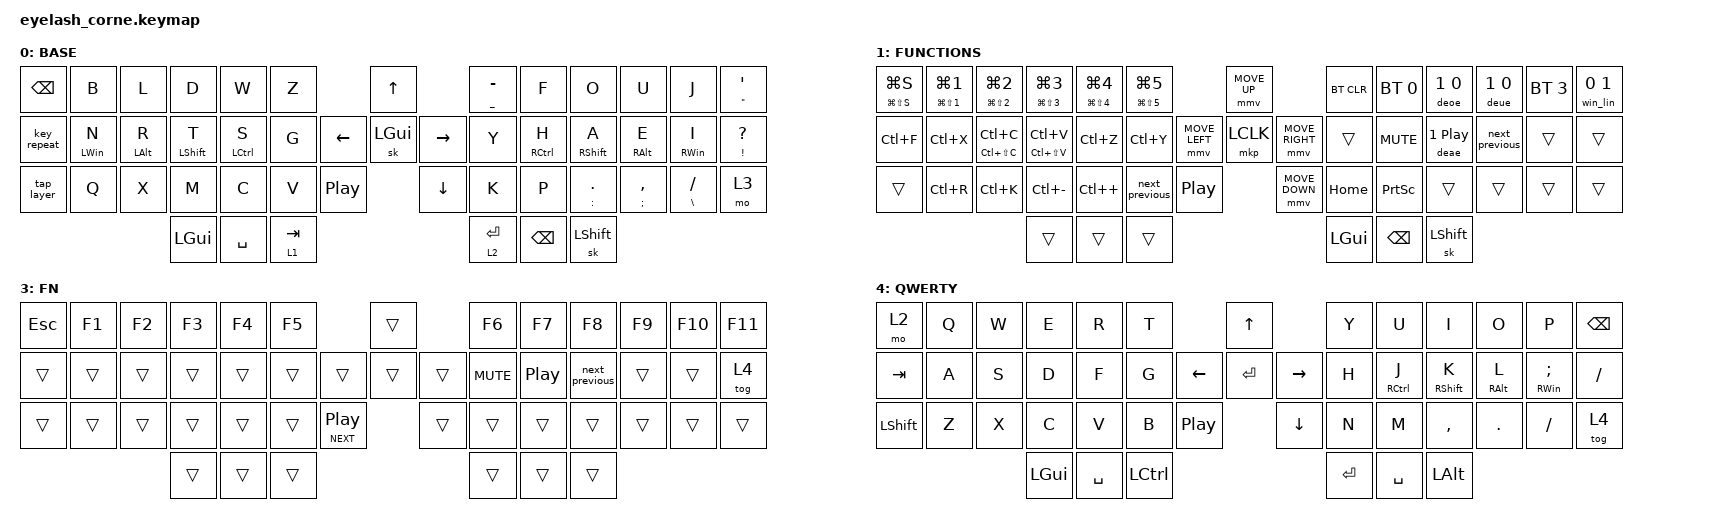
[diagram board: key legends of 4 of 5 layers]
#include <behaviors.dtsi>
#include <behaviors/unicode.dtsi> // for zmk-unicode

/* ----- For default ZMK behavior ---- */
#include <dt-bindings/zmk/bt.h>
#include <dt-bindings/zmk/keys.h>

#include <dt-bindings/zmk/mouse.h>
#include <dt-bindings/zmk/pointing.h>
#include <dt-bindings/zmk/outputs.h>
#include <dt-bindings/zmk/rgb.h>
#include <dt-bindings/zmk/pointing.h>
#include <dt-bindings/zmk/behaviors.h>

/* ----- Extra zmk modules ---- */
#include <zmk-unicode/keys-extra.h>
#include "zmk-helpers/helper.h"
#include <input/processors.dtsi>
#include "zmk-helpers/german.dtsi"
#include "german.dtsi"


/* Mouse input processing default values*/
#undef ZMK_MOUSE_DEFAULT_MOVE_VAL
#undef ZMK_MOUSE_DEFAULT_SCRL_VAL
#define ZMK_MOUSE_DEFAULT_MOVE_VAL 1000  // 600
#define ZMK_MOUSE_DEFAULT_SCRL_VAL 20   // 10

#define ZMK_POINTING_DEFAULT_MOVE_VAL 800  // default: 600
#define ZMK_POINTING_DEFAULT_SCRL_VAL 100    // default: 10
 

&mmv {
  acceleration-exponent = <1>;      // 1
  time-to-max-speed-ms = <500>;     // 300
  delay-ms = <0>;                   // 0
};

&msc {
  acceleration-exponent = <1>;      // 0
  time-to-max-speed-ms = <150>;     // 300
  delay-ms = <0>;                   // 0
};

 &uc {
  default-mode = <UC_MODE_WIN_COMPOSE>;
  minimum-length = <0>; 
}; 

/ {
    behaviors {
        td0: td0 {
            compatible = "zmk,behavior-tap-dance";
            display-name = "Shift/Caps Lock Tap Dance";
            #binding-cells = <0>;
            bindings = <&kp LEFT_SHIFT>, <&kp CAPS>;
        };

        Tab_switching: Tab_switching {
            compatible = "zmk,behavior-sensor-rotate";
            label = "TAB_SWITCHING";
            #sensor-binding-cells = <0>;
            bindings = <&kp LC(LA(TAB))>, <&kp LC(LA(LS(TAB)))>;   
        };

        App_switching: App_switching {
            compatible = "zmk,behavior-sensor-rotate";
            label = "APP_SWITCHING";
            #sensor-binding-cells = <0>;
            bindings = <&kp LG(TAB)>, <&kp LG(LS(TAB))>;
        };

        tap_layer: tap_layer {
            compatible = "zmk,behavior-tap-dance";
            label = "TAP_LAYER";
            #binding-cells = <0>;
            bindings = <&mo 2>, <&kp CAPSLOCK>;
        };

        next_previous: next_previous {
            compatible = "zmk,behavior-tap-dance";
            label = "NEXT_PREVIOUS";
            #binding-cells = <0>;
            bindings = <&kp C_NEXT>, <&kp C_PREVIOUS>;
        };

        rgb_encoder: rgb_encoder {
            compatible = "zmk,behavior-sensor-rotate";
            #sensor-binding-cells = <0>;
            bindings = <&rgb_ug RGB_BRI>, <&rgb_ug RGB_BRD>;
        };


        scroll_encoder: scroll_encoder {
			compatible = "zmk,behavior-sensor-rotate";
			#sensor-binding-cells = <0>;
			bindings = <&msc SCRL_DOWN>, <&msc SCRL_UP>;
			tap-ms = <62>;
		};

        op: op {
            compatible = "zmk,behavior-hold-tap";
            #binding-cells = <2>;
            flavor = "hold-preferred";
            tapping-term-ms = <200>;
            bindings = <&uc>, <&uc>;
            display-name = "Mod-Tap";
        };
    
        
    };

    

    combos { compatible = "zmk,combos"; 

        esc_q_combo: esc_q_combo {
            timeout-ms = <50>;
            key-positions = <0 1>; // positions of the keys in the matrix
            bindings = <&kp ESC>;  // what combo sends
            layers = <0 4>;
        };  

        enter_combo: enter_combo {
            timeout-ms = <50>;
            key-positions = <15 16>; // positions of the keys in the matrix
            bindings = <&kp ENTER>;  // what combo sends

        };

        shift: shift {
            timeout-ms = <50>;
            key-positions = <17 16>; // positions of the keys in the matrix
            bindings = <&sk LEFT_SHIFT>;  // what combo sends
            layers = <0>;

        };

        back {
            bindings = <&kp BACKSPACE>;
            key-positions = <2 3>;
            layers = <0>;
            timeout-ms = <50>;
        };

        del {
            bindings = <&kp DELETE>;
            key-positions = <3 4>;
            layers = <0>;
            timeout-ms = <50>;
        };

        hash {
            bindings = <&kp HASH>;
            key-positions = <16 3>;
            layers = <0>;
            timeout-ms = <50>;
        };

        at {
            bindings = <&kp AT_SIGN>;
            key-positions = <15 2>;
            layers = <0>;
            timeout-ms = <50>;
        };  

    };

    macros {
        bt2: bt2 {
            compatible = "zmk,behavior-macro";
            #binding-cells = <0>;
            bindings = <&bt BT_SEL 2>;
            label = "BT2";
        };
        bt1: bt1 {
            compatible = "zmk,behavior-macro";
            #binding-cells = <0>;
            bindings = <&bt BT_SEL 1>;
            label = "BT1";
        };
        ae: ae {
            compatible = "zmk,behavior-macro";
            #binding-cells = <0>;
            bindings = <&uc UC_DE_AE>;
            label = "ae";
        };
        ue: ue {
            compatible = "zmk,behavior-macro";
            #binding-cells = <0>;
            bindings = <&uc UC_DE_UE>;
            label = "ue";
        };
        oe: oe {
            compatible = "zmk,behavior-macro";
            #binding-cells = <0>;
            bindings = <&uc UC_DE_OE>;
            label = "uoee";
        };
        win: win {
            compatible = "zmk,behavior-macro";
            #binding-cells = <0>;
            bindings = <&uc UC_SET_WIN_COMPOSE>;
            label = "win";
        };
        lin: lin {
            compatible = "zmk,behavior-macro";
            #binding-cells = <0>;
            bindings = <&uc UC_SET_LINUX>;
            label = "lin";
        };
        
        
    };


    keymap {
        compatible = "zmk,keymap";

        default_layer {
            display-name = "BASE";
            bindings = <
&kp BACKSPACE  &kp B            &kp L            &kp D              &kp W              &kp Z                                 &kp UP_ARROW               &hmr UNDER MINUS     &kp F               &kp O                 &kp U                 &kp J                    &hmr DQT APOS
&key_repeat    &hmr LEFT_WIN N  &hmr LEFT_ALT R  &hmr LEFT_SHIFT T  &hmr LCTRL S       &kp G                       &kp LEFT  &sk LGUI     &kp RIGHT     &kp Y                &hmr RCTRL H        &hmr RIGHT_SHIFT A    &hmr RIGHT_ALT E      &hmr RIGHT_WIN I         &hmr EXCL QUESTION
&tap_layer     &kp Q            &kp X            &kp M              &kp C              &kp V      &kp C_PLAY_PAUSE           &kp DOWN                   &kp K                &kp P               &hmr COLON DOT        &hmr SEMI COMMA       &hmr BACKSLASH SLASH     &mo 3
                                                 &kp LGUI           &kp SPACE          &lt 1 TAB                                                        &lt 2 ENTER          &kp BACKSPACE       &sk LEFT_SHIFT
            >;

            sensor-bindings = <&scroll_encoder>;
        };

        lower_layer {   
            display-name = "FUNCTIONS";
            bindings = <
&hmr LG(LS(S)) LG(S)    &hmr LG(LS(N1)) LG(NUMBER_1)  &hmr LG(LS(N2)) LG(NUMBER_2)  &hmr LG(LS(N3)) LG(NUMBER_3)   &hmr LG(LS(N4)) LG(NUMBER_4)   &hmr LG(LS(N5)) LG(NUMBER_5)                              &mmv MOVE_UP                     &bt BT_CLR    &bt BT_SEL 0             &deoe 1 0                &deue 1 0           &bt BT_SEL 3   &win_lin 0 1
&kp LC(F)               &kp LC(X)                     &hmr LC(LS(C)) LC(C)          &hmr LC(LS(V)) LC(V)           &kp LC(Z)                      &kp LC(Y)                                 &mmv MOVE_LEFT  &mkp LCLK    &mmv MOVE_RIGHT     &trans        &kp K_MUTE               &deae 1 C_PLAY_PAUSE     &next_previous      &trans         &trans
&trans                  &kp LC(R)                     &kp LC(K)                     &kp LC(MINUS)                  &kp LC(PLUS)                   &next_previous        &kp C_PLAY_PAUSE                    &mmv MOVE_DOWN                   &kp HOME      &kp PSCRN                &trans                   &trans              &trans         &trans 
                                                                                    &trans                         &trans                         &trans                                                                                     &kp LEFT_GUI  &kp BACKSPACE            &sk LEFT_SHIFT
            >;

            sensor-bindings = <&inc_dec_kp C_VOLUME_UP C_VOL_DN>;
        };

        raise_layer {
            display-name = "SYMBOLS";
            bindings = <
&kp GRAVE  &kp NUMBER_1  &kp NUMBER_2              &kp NUMBER_3             &kp NUMBER_4      &kp N5                                           &msc SCRL_UP                     &kp NUMBER_6        &kp N7               &kp N8                       &kp N9                       &kp N0       &kp BSPC
&kp MINUS  &kp EQUAL     &kp LEFT_PARENTHESIS      &kp RIGHT_PARENTHESIS    &kp BSLH          &kp APOS                        &msc SCRL_LEFT   &kp LG(F)     &msc SCRL_RIGHT    &hmr HOME LC(LEFT)  &kp LEFT_ARROW       &scrl MOVE_Y(40) UP_ARROW    &scrl MOVE_Y(-40) DOWN       &kp RIGHT    &hmr END LC(RIGHT)
&kp COMMA  &kp DOT       &kp LBKT                  &kp RBKT                 &kp FSLH          &sk LEFT_ALT    &kp LG(TAB)                      &msc SCRL_DOWN                   &kp HOME            &hmr PSCRN LG(P)     &trans                       &trans                       &kp END      &kp ENTER
                                               &sk LCTRL              &sk LEFT_SHIFT    &sk LEFT_GUI                                                                      &trans              &trans               &trans
            >;

            sensor-bindings = <&Tab_switching>;
        };

        Fn_layer {
            display-name = "FN";
            bindings = <
&kp ESC  &kp F1  &kp F2  &kp F3  &kp F4  &kp F5                                     &trans          &kp F6      &kp F7            &kp F8          &kp F9  &kp F10  &kp F11
&trans   &trans  &trans  &trans  &trans  &trans                             &trans  &trans  &trans  &kp C_MUTE  &kp C_PLAY_PAUSE  &next_previous  &trans  &trans   &tog 4
&trans   &trans  &trans  &trans  &trans  &trans  &hmr C_NEXT C_PLAY_PAUSE            &trans          &trans      &trans            &trans          &trans  &trans   &trans
                         &trans  &trans  &trans                                                     &trans      &trans            &trans
            >;

            sensor-bindings = <&inc_dec_kp C_VOLUME_UP C_VOL_DN>;
        };

        QWERTY {
            display-name = "QWERTY";
            bindings = <
&mo 2      &kp Q            &kp W             &kp E                &kp R                &kp T                                         &kp UP_ARROW                     &kp Y              &kp U                &kp I                &kp O              &kp P                 &kp BSPC
&kp TAB    &kp A            &kp S             &kp D                &kp F                &kp G                         &kp LEFT_ARROW  &kp ENTER       &kp RIGHT_ARROW  &kp H              &hmr RCTRL J         &hmr RIGHT_SHIFT K   &hmr RIGHT_ALT L   &hmr RIGHT_WIN SEMICOLON   &kp FSLH
&kp LSHFT  &kp Z            &kp X             &kp C                &kp V                &kp B     &kp C_PLAY_PAUSE                    &kp DOWN_ARROW                   &kp N              &kp M                &kp COMMA            &kp DOT            &kp FSLH              &tog 4
                                              &kp LGUI             &kp SPACE            &kp LCTRL                                                                      &kp ENTER          &kp SPACE            &kp LALT
            >;

            sensor-bindings = <&inc_dec_kp C_VOLUME_UP C_VOL_DN>;
        };
    };
};
